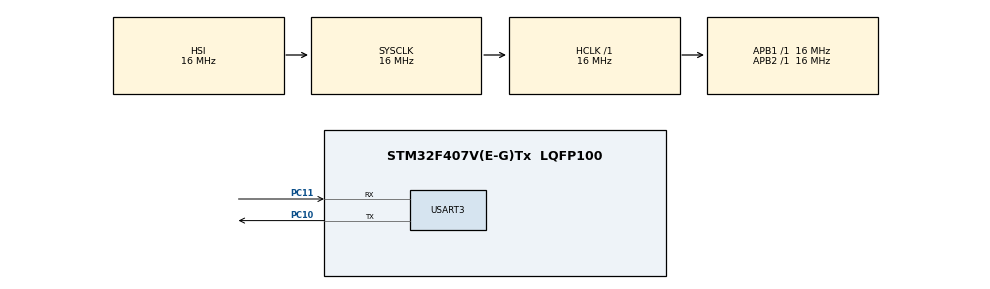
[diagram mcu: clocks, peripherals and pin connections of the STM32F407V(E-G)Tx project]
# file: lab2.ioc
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Mcu.Family=STM32F4
Mcu.Name=STM32F407V(E-G)Tx
Mcu.Package=LQFP100
NVIC.PriorityGroup=NVIC_PRIORITYGROUP_4
PB8.Signal=I2C1_SCL
PB9.Signal=I2C1_SDA
PC10.Mode=Asynchronous
PC10.Signal=USART3_TX
PC11.Mode=Asynchronous
PC11.Signal=USART3_RX
ProjectManager.HeapSize=0x200
ProjectManager.StackSize=0x400
ProjectManager.TargetToolchain=STM32CubeIDE
RCC.AHBFreq_Value=16000000
RCC.APB1Freq_Value=16000000
RCC.APB2Freq_Value=16000000
RCC.CortexFreq_Value=16000000
RCC.HSE_VALUE=25000000
RCC.HSI_VALUE=16000000
RCC.LSE_VALUE=32768
RCC.SYSCLKFreq_VALUE=16000000
RCC.VCOOutputFreq_Value=192000000
USART3.VirtualMode=VM_ASYNC
board=custom

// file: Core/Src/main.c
/* USER CODE BEGIN Header */
/**
  ******************************************************************************
  * @file           : main.c
  * @brief          : Main program body
  ******************************************************************************
  * @attention
  *
  * Copyright (c) 2022 STMicroelectronics.
  * All rights reserved.
  *
  * This software is licensed under terms that can be found in the LICENSE file
  * in the root directory of this software component.
  * If no LICENSE file comes with this software, it is provided AS-IS.
  *
  ******************************************************************************
  */
/* USER CODE END Header */
#include "main.h"

/* USER CODE BEGIN Includes */
#include "ICM20948.h"
//#include <math.h>
/* USER CODE END Includes */

 UART_HandleTypeDef huart3;

void SystemClock_Config(void);
static void MX_GPIO_Init(void);
static void MX_USART3_UART_Init(void);

int main(void)
{
  /* USER CODE BEGIN 1 */
  ICM20948 imu;
  /* USER CODE END 1 */

  /* MCU Configuration--------------------------------------------------------*/

  /* Reset of all peripherals, Initializes the Flash interface and the Systick. */
  HAL_Init();

  /* Configure the system clock */
  SystemClock_Config();

  /* Initialize all configured peripherals */
  MX_GPIO_Init();
  MX_USART3_UART_Init();
  /* USER CODE BEGIN 2 */
  IMU_Initialise(&imu,&hi2c1,&huart3);
  /* USER CODE END 2 */

  /* Infinite loop */
  /* USER CODE BEGIN WHILE */
  //uint8_t temp[35] = "\n\r                                   ";
  uint8_t temp[35] = "\n\r                                ";
  float pitchA, rollA, pitchG, rollG, newTime, oldTime, dT;
  oldTime = pitchG = rollG = pitchA = rollA = 0.0;
  while (1)
  {
	  IMU_AccelRead(&imu);
	  IMU_GyroRead(&imu);
	  pitchA = atan(imu.acc[1]/imu.acc[2]);
	  rollA = atan(imu.acc[0]/imu.acc[2]);

	          //finding change in time used for integrating gyroscope value
	  newTime = HAL_GetTick();
	  dT = newTime-oldTime;
	  oldTime = newTime;

	          //accelerometer

	  pitchA = pitchA/3.14159265*180;
	  rollA = rollA/3.14159265*180;
	  sprintf(&temp[2], "%5.2f", pitchA);
	  sprintf(&temp[10], "%5.2f", rollA);

	          //gyroscope
	  pitchG = pitchG + imu.gyro[1]*dT*0.001;
	  rollG = rollG + imu.gyro[0]*dT*0.001;
	  sprintf(&temp[18], "%5.2f", pitchG);
	  sprintf(&temp[26], "%5.2f", rollG);

	  HAL_UART_Transmit(&huart3,temp,35,HAL_MAX_DELAY);

    /* USER CODE END WHILE */

    /* USER CODE BEGIN 3 */

	  /*char final_p, final_r;
	  sprintf(final_p,"%5.2f ", pitch);
	  sprintf(final_r,"%5.2f ", roll);
	  HAL_UART_Transmit(&huart3,final_p,6,HAL_MAX_DELAY);
	  HAL_UART_Transmit(&huart3,final_r,6,HAL_MAX_DELAY);*/

  }
  /* USER CODE END 3 */
}

void SystemClock_Config(void)
{
  RCC_OscInitTypeDef RCC_OscInitStruct = {0};
  RCC_ClkInitTypeDef RCC_ClkInitStruct = {0};

  /** Configure the main internal regulator output voltage
  */
  __HAL_RCC_PWR_CLK_ENABLE();
  __HAL_PWR_VOLTAGESCALING_CONFIG(PWR_REGULATOR_VOLTAGE_SCALE1);

  /** Initializes the RCC Oscillators according to the specified parameters
  * in the RCC_OscInitTypeDef structure.
  */
  RCC_OscInitStruct.OscillatorType = RCC_OSCILLATORTYPE_HSI;
  RCC_OscInitStruct.HSIState = RCC_HSI_ON;
  RCC_OscInitStruct.HSICalibrationValue = RCC_HSICALIBRATION_DEFAULT;
  RCC_OscInitStruct.PLL.PLLState = RCC_PLL_NONE;
  if (HAL_RCC_OscConfig(&RCC_OscInitStruct) != HAL_OK)
  {
    Error_Handler();
  }

  /** Initializes the CPU, AHB and APB buses clocks
  */
  RCC_ClkInitStruct.ClockType = RCC_CLOCKTYPE_HCLK|RCC_CLOCKTYPE_SYSCLK
                              |RCC_CLOCKTYPE_PCLK1|RCC_CLOCKTYPE_PCLK2;
  RCC_ClkInitStruct.SYSCLKSource = RCC_SYSCLKSOURCE_HSI;
  RCC_ClkInitStruct.AHBCLKDivider = RCC_SYSCLK_DIV1;
  RCC_ClkInitStruct.APB1CLKDivider = RCC_HCLK_DIV1;
  RCC_ClkInitStruct.APB2CLKDivider = RCC_HCLK_DIV1;

  if (HAL_RCC_ClockConfig(&RCC_ClkInitStruct, FLASH_LATENCY_0) != HAL_OK)
  {
    Error_Handler();
  }
}

static void MX_USART3_UART_Init(void)
{

  huart3.Instance = USART3;
  huart3.Init.BaudRate = 115200;
  huart3.Init.WordLength = UART_WORDLENGTH_8B;
  huart3.Init.StopBits = UART_STOPBITS_1;
  huart3.Init.Parity = UART_PARITY_NONE;
  huart3.Init.Mode = UART_MODE_TX_RX;
  huart3.Init.HwFlowCtl = UART_HWCONTROL_NONE;
  huart3.Init.OverSampling = UART_OVERSAMPLING_16;
  if (HAL_UART_Init(&huart3) != HAL_OK)
  {
    Error_Handler();
  }

}

static void MX_GPIO_Init(void)
{
  GPIO_InitTypeDef GPIO_InitStruct = {0};

  /* GPIO Ports Clock Enable */
  __HAL_RCC_GPIOC_CLK_ENABLE();
  __HAL_RCC_GPIOB_CLK_ENABLE();

  /*Configure GPIO pins : PB8 PB9 */
  GPIO_InitStruct.Pin = GPIO_PIN_8|GPIO_PIN_9;
  GPIO_InitStruct.Mode = GPIO_MODE_AF_OD;
  GPIO_InitStruct.Pull = GPIO_NOPULL;
  GPIO_InitStruct.Speed = GPIO_SPEED_FREQ_VERY_HIGH;
  GPIO_InitStruct.Alternate = GPIO_AF4_I2C1;
  HAL_GPIO_Init(GPIOB, &GPIO_InitStruct);

}

void Error_Handler(void)
{
  __disable_irq();
  while (1)
  {
  }
}
